AUTOSAR XML (schema 00048)
package /ComponentTypes
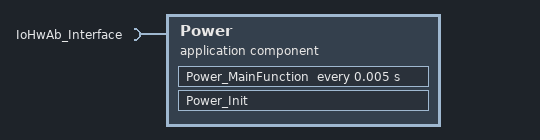
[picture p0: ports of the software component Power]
  application sw component type Power
    require port IoHwAb_Interface: required-com-specs=[SetHsLsOutput, SetPeriodAndDuty, SetDuty, SetPin, GetPin, GetVoltage], required-interface=IoHwAb_Interface
    behavior Power_InternalBehavior
      init event Power_InitEvent: start-on-event=Power_Init
      timing event TMT_Power_MainFunction: start-on-event=Power_MainFunction, period=0.005
      runnable Power_Init
      runnable Power_MainFunction
        sync call SC_IoHwAb_Interface_GetVoltage: operation=IoHwAb_Interface.GetVoltage
  swc implementation Power_Implementation: behavior=Power_InternalBehavior
